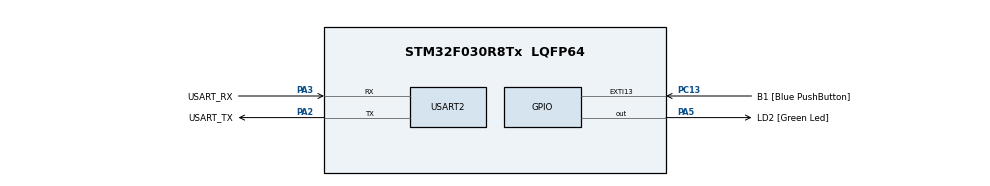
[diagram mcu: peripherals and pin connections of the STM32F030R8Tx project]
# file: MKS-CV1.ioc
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Mcu.Family=STM32F0
Mcu.Name=STM32F030R8Tx
Mcu.Package=LQFP64
PA13.GPIO_Label=TMS
PA13.Mode=Serial_Wire
PA13.Signal=SYS_SWDIO
PA14.GPIO_Label=TCK
PA14.Mode=Serial_Wire
PA14.Signal=SYS_SWCLK
PA2.GPIO_Label=USART_TX
PA2.GPIO_Mode=GPIO_MODE_AF_PP
PA2.GPIO_PuPd=GPIO_NOPULL
PA2.GPIO_Speed=GPIO_SPEED_FREQ_LOW
PA2.Mode=Asynchronous
PA2.Signal=USART2_TX
PA3.GPIO_Label=USART_RX
PA3.GPIO_Mode=GPIO_MODE_AF_PP
PA3.GPIO_PuPd=GPIO_NOPULL
PA3.GPIO_Speed=GPIO_SPEED_FREQ_LOW
PA3.Mode=Asynchronous
PA3.Signal=USART2_RX
PA5.GPIO_Label=LD2 [Green Led]
PA5.GPIO_Mode=GPIO_MODE_OUTPUT_PP
PA5.GPIO_PuPd=GPIO_NOPULL
PA5.GPIO_Speed=GPIO_SPEED_FREQ_LOW
PA5.Signal=GPIO_Output
PC13.GPIO_Label=B1 [Blue PushButton]
PC13.GPIO_ModeDefaultEXTI=GPIO_MODE_IT_FALLING
PC13.Signal=GPXTI13
PC14-OSC32_IN.Mode=LSE-External-Oscillator
PC14-OSC32_IN.Signal=RCC_OSC32_IN
PC15-OSC32_OUT.Mode=LSE-External-Oscillator
PC15-OSC32_OUT.Signal=RCC_OSC32_OUT
PF0-OSC_IN.Mode=HSE-External-Clock-Source
PF0-OSC_IN.Signal=RCC_OSC_IN
PF1-OSC_OUT.Signal=RCC_OSC_OUT
ProjectManager.HeapSize=0x200
ProjectManager.StackSize=0x400
ProjectManager.TargetToolchain=STM32CubeIDE
RCC.AHBFreq_Value=48000000
RCC.APB1Freq_Value=48000000
RCC.APB1TimFreq_Value=48000000
RCC.HCLKFreq_Value=48000000
RCC.PLLMUL=RCC_PLL_MUL12
RCC.SYSCLKFreq_VALUE=48000000
RCC.SYSCLKSource=RCC_SYSCLKSOURCE_PLLCLK
USART2.VirtualMode-Asynchronous=VM_ASYNC
board=NUCLEO-F030R8

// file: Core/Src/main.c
/* USER CODE BEGIN Header */
/**
  ******************************************************************************
  * @file           : main.c
  * @brief          : Main program body
  ******************************************************************************
  * @attention
  *
  * Copyright (c) 2023 STMicroelectronics.
  * All rights reserved.
  *
  * This software is licensed under terms that can be found in the LICENSE file
  * in the root directory of this software component.
  * If no LICENSE file comes with this software, it is provided AS-IS.
  *
  ******************************************************************************
  */
/* USER CODE END Header */
#include "main.h"

void SystemClock_Config(void);
static void MX_GPIO_Init(void);
static void MX_USART2_UART_Init(void);

int main(void)
{

  /* MCU Configuration--------------------------------------------------------*/

  /* Reset of all peripherals, Initializes the Flash interface and the Systick. */
  LL_APB1_GRP2_EnableClock(LL_APB1_GRP2_PERIPH_SYSCFG);
  LL_APB1_GRP1_EnableClock(LL_APB1_GRP1_PERIPH_PWR);

  /* USER CODE BEGIN Init */
  	 // uint8_t pole[32] = {1,0,1,0,1,0,0,1,1,1,0,1,1,1,0,1,1,1,0,0,1,0,1,0,1,0,0,0,0,0,0,0};
  	  uint32_t delay = 200;
  	  uint32_t sos = 0b000000001010100111011101110010101;
  /* USER CODE END Init */

  /* Configure the system clock */
  SystemClock_Config();

  /* Initialize all configured peripherals */
  MX_GPIO_Init();
  MX_USART2_UART_Init();

  /* Infinite loop */
  while (1)
  {
	  for(unint32_t i = 0; i < 32; i++)
	  {
		  if(((sos >> i) & 1) == 1)
		  {
			  LL_GPIO_SetOutputPin(LD2_GPIO_Port, LD2_Pin);
		  }
		  LL_mDelay(delay);
		  LL_GPIO_ResetOutputPin(LD2_GPIO_Port, LD2_Pin);

	  }
  }
}

void SystemClock_Config(void)
{
  LL_FLASH_SetLatency(LL_FLASH_LATENCY_1);
  while(LL_FLASH_GetLatency() != LL_FLASH_LATENCY_1)
  {
  }
  LL_RCC_HSI_Enable();

   /* Wait till HSI is ready */
  while(LL_RCC_HSI_IsReady() != 1)
  {

  }
  LL_RCC_HSI_SetCalibTrimming(16);
  LL_RCC_PLL_ConfigDomain_SYS(LL_RCC_PLLSOURCE_HSI_DIV_2, LL_RCC_PLL_MUL_12);
  LL_RCC_PLL_Enable();

   /* Wait till PLL is ready */
  while(LL_RCC_PLL_IsReady() != 1)
  {

  }
  LL_RCC_SetAHBPrescaler(LL_RCC_SYSCLK_DIV_1);
  LL_RCC_SetAPB1Prescaler(LL_RCC_APB1_DIV_1);
  LL_RCC_SetSysClkSource(LL_RCC_SYS_CLKSOURCE_PLL);

   /* Wait till System clock is ready */
  while(LL_RCC_GetSysClkSource() != LL_RCC_SYS_CLKSOURCE_STATUS_PLL)
  {

  }
  LL_Init1msTick(48000000);
  LL_SetSystemCoreClock(48000000);
}

static void MX_USART2_UART_Init(void)
{

  LL_USART_InitTypeDef USART_InitStruct = {0};

  LL_GPIO_InitTypeDef GPIO_InitStruct = {0};

  /* Peripheral clock enable */
  LL_APB1_GRP1_EnableClock(LL_APB1_GRP1_PERIPH_USART2);

  LL_AHB1_GRP1_EnableClock(LL_AHB1_GRP1_PERIPH_GPIOA);
  /**USART2 GPIO Configuration
  PA2   ------> USART2_TX
  PA3   ------> USART2_RX
  */
  GPIO_InitStruct.Pin = USART_TX_Pin;
  GPIO_InitStruct.Mode = LL_GPIO_MODE_ALTERNATE;
  GPIO_InitStruct.Speed = LL_GPIO_SPEED_FREQ_LOW;
  GPIO_InitStruct.OutputType = LL_GPIO_OUTPUT_PUSHPULL;
  GPIO_InitStruct.Pull = LL_GPIO_PULL_NO;
  GPIO_InitStruct.Alternate = LL_GPIO_AF_1;
  LL_GPIO_Init(USART_TX_GPIO_Port, &GPIO_InitStruct);

  GPIO_InitStruct.Pin = USART_RX_Pin;
  GPIO_InitStruct.Mode = LL_GPIO_MODE_ALTERNATE;
  GPIO_InitStruct.Speed = LL_GPIO_SPEED_FREQ_LOW;
  GPIO_InitStruct.OutputType = LL_GPIO_OUTPUT_PUSHPULL;
  GPIO_InitStruct.Pull = LL_GPIO_PULL_NO;
  GPIO_InitStruct.Alternate = LL_GPIO_AF_1;
  LL_GPIO_Init(USART_RX_GPIO_Port, &GPIO_InitStruct);

  USART_InitStruct.BaudRate = 38400;
  USART_InitStruct.DataWidth = LL_USART_DATAWIDTH_8B;
  USART_InitStruct.StopBits = LL_USART_STOPBITS_1;
  USART_InitStruct.Parity = LL_USART_PARITY_NONE;
  USART_InitStruct.TransferDirection = LL_USART_DIRECTION_TX_RX;
  USART_InitStruct.HardwareFlowControl = LL_USART_HWCONTROL_NONE;
  USART_InitStruct.OverSampling = LL_USART_OVERSAMPLING_16;
  LL_USART_Init(USART2, &USART_InitStruct);
  LL_USART_DisableIT_CTS(USART2);
  LL_USART_ConfigAsyncMode(USART2);
  LL_USART_Enable(USART2);

}

static void MX_GPIO_Init(void)
{
  LL_EXTI_InitTypeDef EXTI_InitStruct = {0};
  LL_GPIO_InitTypeDef GPIO_InitStruct = {0};

  /* GPIO Ports Clock Enable */
  LL_AHB1_GRP1_EnableClock(LL_AHB1_GRP1_PERIPH_GPIOC);
  LL_AHB1_GRP1_EnableClock(LL_AHB1_GRP1_PERIPH_GPIOF);
  LL_AHB1_GRP1_EnableClock(LL_AHB1_GRP1_PERIPH_GPIOA);

  /**/
  LL_GPIO_ResetOutputPin(LD2_GPIO_Port, LD2_Pin);

  /**/
  LL_SYSCFG_SetEXTISource(LL_SYSCFG_EXTI_PORTC, LL_SYSCFG_EXTI_LINE13);

  /**/
  LL_GPIO_SetPinPull(B1_GPIO_Port, B1_Pin, LL_GPIO_PULL_NO);

  /**/
  LL_GPIO_SetPinMode(B1_GPIO_Port, B1_Pin, LL_GPIO_MODE_INPUT);

  /**/
  EXTI_InitStruct.Line_0_31 = LL_EXTI_LINE_13;
  EXTI_InitStruct.LineCommand = ENABLE;
  EXTI_InitStruct.Mode = LL_EXTI_MODE_IT;
  EXTI_InitStruct.Trigger = LL_EXTI_TRIGGER_FALLING;
  LL_EXTI_Init(&EXTI_InitStruct);

  /**/
  GPIO_InitStruct.Pin = LD2_Pin;
  GPIO_InitStruct.Mode = LL_GPIO_MODE_OUTPUT;
  GPIO_InitStruct.Speed = LL_GPIO_SPEED_FREQ_LOW;
  GPIO_InitStruct.OutputType = LL_GPIO_OUTPUT_PUSHPULL;
  GPIO_InitStruct.Pull = LL_GPIO_PULL_NO;
  LL_GPIO_Init(LD2_GPIO_Port, &GPIO_InitStruct);

}

void Error_Handler(void)
{
  __disable_irq();
  while (1)
  {
  }
}
